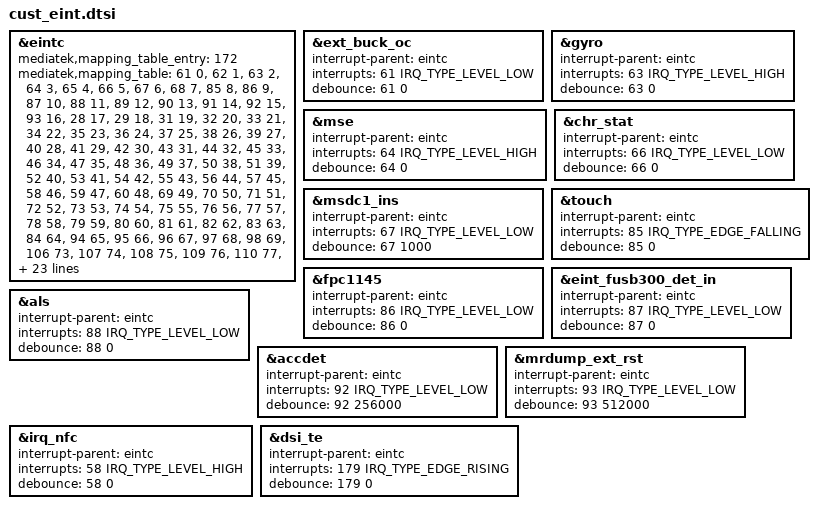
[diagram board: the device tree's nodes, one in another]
/*
 * Generated by MTK SP DrvGen Version: 2.2.160113 for MT6797. Copyright MediaTek Inc. (C) 2015.
 * 01.18.2022 23:42:18
 * Do Not Modify the File.
 */

/*************************
 * EINT DTSI File
*************************/

#include <dt-bindings/interrupt-controller/irq.h>
#include <dt-bindings/interrupt-controller/arm-gic.h>

&eintc {
	mediatek,mapping_table_entry = <172>;
			/* <gpio_pin, eint_pin> */
	mediatek,mapping_table = <61 0>,
					<62 1>,
					<63 2>,
					<64 3>,
					<65 4>,
					<66 5>,
					<67 6>,
					<68 7>,
					<85 8>,
					<86 9>,
					<87 10>,
					<88 11>,
					<89 12>,
					<90 13>,
					<91 14>,
					<92 15>,
					<93 16>,
					<28 17>,
					<29 18>,
					<31 19>,
					<32 20>,
					<33 21>,
					<34 22>,
					<35 23>,
					<36 24>,
					<37 25>,
					<38 26>,
					<39 27>,
					<40 28>,
					<41 29>,
					<42 30>,
					<43 31>,
					<44 32>,
					<45 33>,
					<46 34>,
					<47 35>,
					<48 36>,
					<49 37>,
					<50 38>,
					<51 39>,
					<52 40>,
					<53 41>,
					<54 42>,
					<55 43>,
					<56 44>,
					<57 45>,
					<58 46>,
					<59 47>,
					<60 48>,
					<69 49>,
					<70 50>,
					<71 51>,
					<72 52>,
					<73 53>,
					<74 54>,
					<75 55>,
					<76 56>,
					<77 57>,
					<78 58>,
					<79 59>,
					<80 60>,
					<81 61>,
					<82 62>,
					<83 63>,
					<84 64>,
					<94 65>,
					<95 66>,
					<96 67>,
					<97 68>,
					<98 69>,
					<106 73>,
					<107 74>,
					<108 75>,
					<109 76>,
					<110 77>,
					<111 78>,
					<112 79>,
					<113 80>,
					<126 81>,
					<127 82>,
					<128 83>,
					<129 84>,
					<130 85>,
					<131 86>,
					<132 87>,
					<133 88>,
					<134 89>,
					<135 90>,
					<136 91>,
					<137 92>,
					<138 93>,
					<139 94>,
					<140 95>,
					<141 96>,
					<151 97>,
					<152 98>,
					<153 99>,
					<154 100>,
					<155 101>,
					<156 102>,
					<157 103>,
					<179 104>,
					<180 105>,
					<181 106>,
					<183 107>,
					<184 108>,
					<185 109>,
					<186 110>,
					<187 111>,
					<188 112>,
					<189 113>,
					<190 114>,
					<191 115>,
					<192 116>,
					<193 117>,
					<194 118>,
					<195 119>,
					<196 120>,
					<197 121>,
					<198 122>,
					<199 123>,
					<200 124>,
					<201 125>,
					<202 126>,
					<203 127>,
					<204 128>,
					<205 129>,
					<206 130>,
					<207 131>,
					<208 132>,
					<209 133>,
					<210 134>,
					<211 135>,
					<212 136>,
					<213 137>,
					<214 138>,
					<215 139>,
					<216 140>,
					<217 141>,
					<218 142>,
					<219 143>,
					<232 144>,
					<233 145>,
					<234 146>,
					<235 147>,
					<236 148>,
					<237 149>,
					<238 150>,
					<239 151>,
					<240 152>,
					<241 153>,
					<242 154>,
					<243 155>,
					<244 156>,
					<245 157>,
					<246 158>,
					<247 159>,
					<248 160>,
					<249 161>,
					<250 162>,
					<251 163>,
					<252 164>,
					<253 165>,
					<254 166>,
					<255 167>,
					<256 168>,
					<257 169>,
					<258 170>,
					<259 171>,
					<260 172>,
					<261 173>,
					<262 176>;
	mediatek,builtin_entry = <4>;	/* gpio, built-in func mode, built-in eint */
	mediatek,builtin_mapping = <61 2 186>, /* 2:IDDIG */
					<93 2 186>, /* 2:IDDIG */
					<107 2 186>, /* 2:IDDIG */
					<181 1 186>; /* 1:IDDIG */
};

&ext_buck_oc {
	interrupt-parent = <&eintc>;
	interrupts = <61 IRQ_TYPE_LEVEL_LOW>;
	debounce = <61 0>;
	status = "okay";
};
&gyro {
	interrupt-parent = <&eintc>;
	interrupts = <63 IRQ_TYPE_LEVEL_HIGH>;
	debounce = <63 0>;
	status = "okay";
};
&mse {
	interrupt-parent = <&eintc>;
	interrupts = <64 IRQ_TYPE_LEVEL_HIGH>;
	debounce = <64 0>;
	status = "okay";
};
&chr_stat {
	interrupt-parent = <&eintc>;
	interrupts = <66 IRQ_TYPE_LEVEL_LOW>;
	debounce = <66 0>;
	status = "okay";
};
&msdc1_ins {
	interrupt-parent = <&eintc>;
	interrupts = <67 IRQ_TYPE_LEVEL_LOW>;
	debounce = <67 1000>;
	status = "okay";
};
&touch {
	interrupt-parent = <&eintc>;
	interrupts = <85 IRQ_TYPE_EDGE_FALLING>;
	debounce = <85 0>;
	status = "okay";
};
&fpc1145 {
	interrupt-parent = <&eintc>;
	interrupts = <86 IRQ_TYPE_LEVEL_LOW>;
	debounce = <86 0>;
	status = "okay";
};
&eint_fusb300_det_in {
	interrupt-parent = <&eintc>;
	interrupts = <87 IRQ_TYPE_LEVEL_LOW>;
	debounce = <87 0>;
	status = "okay";
};
&als {
	interrupt-parent = <&eintc>;
	interrupts = <88 IRQ_TYPE_LEVEL_LOW>;
	debounce = <88 0>;
	status = "okay";
};
&accdet {
	interrupt-parent = <&eintc>;
	interrupts = <92 IRQ_TYPE_LEVEL_LOW>;
	debounce = <92 256000>;
	status = "okay";
};
&mrdump_ext_rst {
	interrupt-parent = <&eintc>;
	interrupts = <93 IRQ_TYPE_LEVEL_LOW>;
	debounce = <93 512000>;
	status = "okay";
};
&irq_nfc {
	interrupt-parent = <&eintc>;
	interrupts = <58 IRQ_TYPE_LEVEL_HIGH>;
	debounce = <58 0>;
	status = "okay";
};
&dsi_te {
	interrupt-parent = <&eintc>;
	interrupts = <179 IRQ_TYPE_EDGE_RISING>;
	debounce = <179 0>;
	status = "okay";
};

